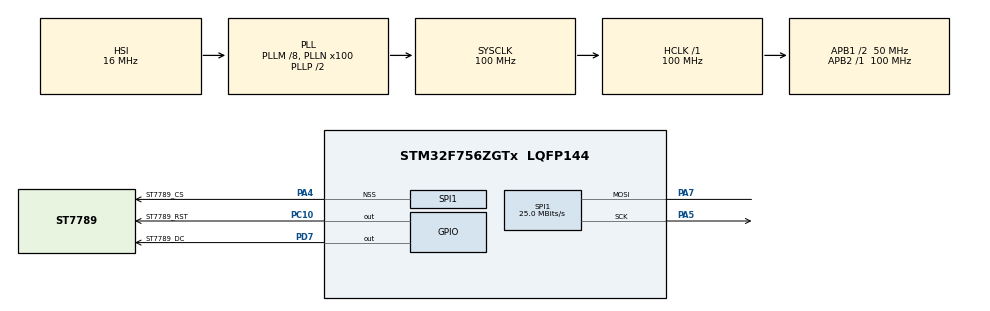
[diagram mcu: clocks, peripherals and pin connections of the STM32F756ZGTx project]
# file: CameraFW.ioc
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CORTEX_M7.default_mode_Activation=1
Dma.Request0=SPI1_TX
Dma.SPI1_TX.0.Direction=DMA_MEMORY_TO_PERIPH
Dma.SPI1_TX.0.FIFOMode=DMA_FIFOMODE_ENABLE
Dma.SPI1_TX.0.FIFOThreshold=DMA_FIFO_THRESHOLD_FULL
Dma.SPI1_TX.0.Instance=DMA2_Stream3
Dma.SPI1_TX.0.MemBurst=DMA_MBURST_SINGLE
Dma.SPI1_TX.0.MemDataAlignment=DMA_MDATAALIGN_HALFWORD
Dma.SPI1_TX.0.MemInc=DMA_MINC_ENABLE
Dma.SPI1_TX.0.Mode=DMA_NORMAL
Dma.SPI1_TX.0.PeriphBurst=DMA_PBURST_SINGLE
Dma.SPI1_TX.0.PeriphDataAlignment=DMA_PDATAALIGN_HALFWORD
Dma.SPI1_TX.0.PeriphInc=DMA_PINC_DISABLE
Dma.SPI1_TX.0.Priority=DMA_PRIORITY_LOW
Mcu.Family=STM32F7
Mcu.Name=STM32F756ZGTx
Mcu.Package=LQFP144
NVIC.DMA2_Stream3_IRQn=true\:0\:0\:false\:false\:true\:false\:true\:true
NVIC.PriorityGroup=NVIC_PRIORITYGROUP_4
PA13.Mode=Trace_Asynchronous_SW
PA13.Signal=SYS_JTMS-SWDIO
PA14.Mode=Trace_Asynchronous_SW
PA14.Signal=SYS_JTCK-SWCLK
PA4.GPIO_Label=ST7789_CS
PA4.Mode=NSS_Signal_Hard_Output
PA4.Signal=SPI1_NSS
PA5.Mode=Simplex_Bidirectional_Master
PA5.Signal=SPI1_SCK
PA7.Mode=Simplex_Bidirectional_Master
PA7.Signal=SPI1_MOSI
PB3.Mode=Trace_Asynchronous_SW
PB3.Signal=SYS_JTDO-SWO
PC10.GPIO_Label=ST7789_RST
PC10.Signal=GPIO_Output
PD7.GPIO_Label=ST7789_DC
PD7.Signal=GPIO_Output
ProjectManager.HeapSize=0x200
ProjectManager.StackSize=0x400
ProjectManager.TargetToolchain=STM32CubeIDE
RCC.AHBFreq_Value=100000000
RCC.APB1CLKDivider=RCC_HCLK_DIV2
RCC.APB1Freq_Value=50000000
RCC.APB1TimFreq_Value=100000000
RCC.APB2Freq_Value=100000000
RCC.APB2TimFreq_Value=100000000
RCC.CortexFreq_Value=100000000
RCC.HCLKFreq_Value=100000000
RCC.HSE_VALUE=25000000
RCC.HSI_VALUE=16000000
RCC.LSE_VALUE=32768
RCC.PLLM=8
RCC.PLLN=100
RCC.SYSCLKFreq_VALUE=100000000
RCC.SYSCLKSource=RCC_SYSCLKSOURCE_PLLCLK
RCC.USBFreq_Value=100000000
RCC.VCOOutputFreq_Value=200000000
SPI1.BaudRatePrescaler=SPI_BAUDRATEPRESCALER_4
SPI1.CLKPolarity=SPI_POLARITY_HIGH
SPI1.CalculateBaudRate=25.0 MBits/s
SPI1.DataSize=SPI_DATASIZE_8BIT
SPI1.Direction=SPI_DIRECTION_1LINE
SPI1.Mode=SPI_MODE_MASTER
SPI1.VirtualNSS=VM_NSSHARD
SPI1.VirtualType=VM_MASTER
board=custom

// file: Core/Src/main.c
/* USER CODE BEGIN Header */
/**
  ******************************************************************************
  * @file           : main.c
  * @brief          : Main program body
  ******************************************************************************
  * @attention
  *
  * Copyright (c) 2025 STMicroelectronics.
  * All rights reserved.
  *
  * This software is licensed under terms that can be found in the LICENSE file
  * in the root directory of this software component.
  * If no LICENSE file comes with this software, it is provided AS-IS.
  *
  ******************************************************************************
  */
/* USER CODE END Header */
#include "main.h"
#include "st7789.h"

SPI_HandleTypeDef hspi1;
DMA_HandleTypeDef hdma_spi1_tx;

void SystemClock_Config(void);
static void MPU_Config(void);
static void MX_GPIO_Init(void);
static void MX_DMA_Init(void);
static void MX_SPI1_Init(void);

int main(void)
{

  /* MPU Configuration--------------------------------------------------------*/
  MPU_Config();

  /* MCU Configuration--------------------------------------------------------*/

  /* Reset of all peripherals, Initializes the Flash interface and the Systick. */
  HAL_Init();

  /* Configure the system clock */
  SystemClock_Config();

  /* Initialize all configured peripherals */
  MX_GPIO_Init();
  MX_DMA_Init();
  MX_SPI1_Init();
  /* USER CODE BEGIN 2 */

  ST7789_Init();

  /* USER CODE END 2 */

  /* Infinite loop */
  while (1)
  {
	ST7789_Test();

  }
}

void SystemClock_Config(void)
{
  RCC_OscInitTypeDef RCC_OscInitStruct = {0};
  RCC_ClkInitTypeDef RCC_ClkInitStruct = {0};

  /** Configure the main internal regulator output voltage
  */
  __HAL_RCC_PWR_CLK_ENABLE();
  __HAL_PWR_VOLTAGESCALING_CONFIG(PWR_REGULATOR_VOLTAGE_SCALE3);

  /** Initializes the RCC Oscillators according to the specified parameters
  * in the RCC_OscInitTypeDef structure.
  */
  RCC_OscInitStruct.OscillatorType = RCC_OSCILLATORTYPE_HSI;
  RCC_OscInitStruct.HSIState = RCC_HSI_ON;
  RCC_OscInitStruct.HSICalibrationValue = RCC_HSICALIBRATION_DEFAULT;
  RCC_OscInitStruct.PLL.PLLState = RCC_PLL_ON;
  RCC_OscInitStruct.PLL.PLLSource = RCC_PLLSOURCE_HSI;
  RCC_OscInitStruct.PLL.PLLM = 8;
  RCC_OscInitStruct.PLL.PLLN = 100;
  RCC_OscInitStruct.PLL.PLLP = RCC_PLLP_DIV2;
  RCC_OscInitStruct.PLL.PLLQ = 2;
  if (HAL_RCC_OscConfig(&RCC_OscInitStruct) != HAL_OK)
  {
    Error_Handler();
  }

  /** Activate the Over-Drive mode
  */
  if (HAL_PWREx_EnableOverDrive() != HAL_OK)
  {
    Error_Handler();
  }

  /** Initializes the CPU, AHB and APB buses clocks
  */
  RCC_ClkInitStruct.ClockType = RCC_CLOCKTYPE_HCLK|RCC_CLOCKTYPE_SYSCLK
                              |RCC_CLOCKTYPE_PCLK1|RCC_CLOCKTYPE_PCLK2;
  RCC_ClkInitStruct.SYSCLKSource = RCC_SYSCLKSOURCE_PLLCLK;
  RCC_ClkInitStruct.AHBCLKDivider = RCC_SYSCLK_DIV1;
  RCC_ClkInitStruct.APB1CLKDivider = RCC_HCLK_DIV2;
  RCC_ClkInitStruct.APB2CLKDivider = RCC_HCLK_DIV1;

  if (HAL_RCC_ClockConfig(&RCC_ClkInitStruct, FLASH_LATENCY_3) != HAL_OK)
  {
    Error_Handler();
  }
}

static void MX_SPI1_Init(void)
{

  /* SPI1 parameter configuration*/
  hspi1.Instance = SPI1;
  hspi1.Init.Mode = SPI_MODE_MASTER;
  hspi1.Init.Direction = SPI_DIRECTION_1LINE;
  hspi1.Init.DataSize = SPI_DATASIZE_8BIT;
  hspi1.Init.CLKPolarity = SPI_POLARITY_HIGH;
  hspi1.Init.CLKPhase = SPI_PHASE_1EDGE;
  hspi1.Init.NSS = SPI_NSS_HARD_OUTPUT;
  hspi1.Init.BaudRatePrescaler = SPI_BAUDRATEPRESCALER_4;
  hspi1.Init.FirstBit = SPI_FIRSTBIT_MSB;
  hspi1.Init.TIMode = SPI_TIMODE_DISABLE;
  hspi1.Init.CRCCalculation = SPI_CRCCALCULATION_DISABLE;
  hspi1.Init.CRCPolynomial = 7;
  hspi1.Init.CRCLength = SPI_CRC_LENGTH_DATASIZE;
  hspi1.Init.NSSPMode = SPI_NSS_PULSE_ENABLE;
  if (HAL_SPI_Init(&hspi1) != HAL_OK)
  {
    Error_Handler();
  }

}

static void MX_DMA_Init(void)
{

  /* DMA controller clock enable */
  __HAL_RCC_DMA2_CLK_ENABLE();

  /* DMA interrupt init */
  /* DMA2_Stream3_IRQn interrupt configuration */
  HAL_NVIC_SetPriority(DMA2_Stream3_IRQn, 0, 0);
  HAL_NVIC_EnableIRQ(DMA2_Stream3_IRQn);

}

static void MX_GPIO_Init(void)
{
  GPIO_InitTypeDef GPIO_InitStruct = {0};

  /* GPIO Ports Clock Enable */
  __HAL_RCC_GPIOA_CLK_ENABLE();
  __HAL_RCC_GPIOC_CLK_ENABLE();
  __HAL_RCC_GPIOD_CLK_ENABLE();
  __HAL_RCC_GPIOB_CLK_ENABLE();

  /*Configure GPIO pin Output Level */
  HAL_GPIO_WritePin(ST7789_RST_GPIO_Port, ST7789_RST_Pin, GPIO_PIN_RESET);

  /*Configure GPIO pin Output Level */
  HAL_GPIO_WritePin(ST7789_DC_GPIO_Port, ST7789_DC_Pin, GPIO_PIN_RESET);

  /*Configure GPIO pin : ST7789_RST_Pin */
  GPIO_InitStruct.Pin = ST7789_RST_Pin;
  GPIO_InitStruct.Mode = GPIO_MODE_OUTPUT_PP;
  GPIO_InitStruct.Pull = GPIO_NOPULL;
  GPIO_InitStruct.Speed = GPIO_SPEED_FREQ_LOW;
  HAL_GPIO_Init(ST7789_RST_GPIO_Port, &GPIO_InitStruct);

  /*Configure GPIO pin : ST7789_DC_Pin */
  GPIO_InitStruct.Pin = ST7789_DC_Pin;
  GPIO_InitStruct.Mode = GPIO_MODE_OUTPUT_PP;
  GPIO_InitStruct.Pull = GPIO_NOPULL;
  GPIO_InitStruct.Speed = GPIO_SPEED_FREQ_LOW;
  HAL_GPIO_Init(ST7789_DC_GPIO_Port, &GPIO_InitStruct);

}

 /* MPU Configuration */

void MPU_Config(void)
{
  MPU_Region_InitTypeDef MPU_InitStruct = {0};

  /* Disables the MPU */
  HAL_MPU_Disable();

  /** Initializes and configures the Region and the memory to be protected
  */
  MPU_InitStruct.Enable = MPU_REGION_ENABLE;
  MPU_InitStruct.Number = MPU_REGION_NUMBER0;
  MPU_InitStruct.BaseAddress = 0x0;
  MPU_InitStruct.Size = MPU_REGION_SIZE_4GB;
  MPU_InitStruct.SubRegionDisable = 0x87;
  MPU_InitStruct.TypeExtField = MPU_TEX_LEVEL0;
  MPU_InitStruct.AccessPermission = MPU_REGION_NO_ACCESS;
  MPU_InitStruct.DisableExec = MPU_INSTRUCTION_ACCESS_DISABLE;
  MPU_InitStruct.IsShareable = MPU_ACCESS_SHAREABLE;
  MPU_InitStruct.IsCacheable = MPU_ACCESS_NOT_CACHEABLE;
  MPU_InitStruct.IsBufferable = MPU_ACCESS_NOT_BUFFERABLE;

  HAL_MPU_ConfigRegion(&MPU_InitStruct);
  /* Enables the MPU */
  HAL_MPU_Enable(MPU_PRIVILEGED_DEFAULT);

}

void Error_Handler(void)
{
  __disable_irq();
  while (1)
  {
  }
}
